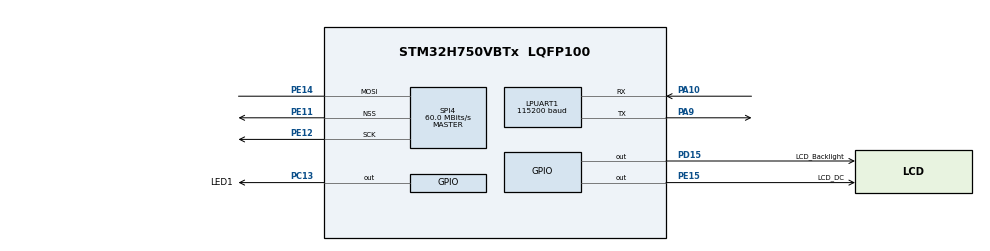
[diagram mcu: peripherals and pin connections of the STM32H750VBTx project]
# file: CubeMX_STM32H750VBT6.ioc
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CORTEX_M7.CPU_DCache=Enabled
CORTEX_M7.CPU_ICache=Enabled
CORTEX_M7.Enable-Cortex_Memory_Protection_Unit_Region0_Settings=MPU_REGION_ENABLE
CORTEX_M7.MPU_Control=__NULL
LPUART1.BaudRate=115200
Mcu.Family=STM32H7
Mcu.Name=STM32H750VBTx
Mcu.Package=LQFP100
NVIC.LPUART1_IRQn=true\:0\:0\:false\:false\:true\:true\:true\:true
NVIC.PriorityGroup=NVIC_PRIORITYGROUP_4
PA10.Mode=Asynchronous
PA10.Signal=LPUART1_RX
PA13\ (JTMS/SWDIO).Mode=Serial_Wire
PA13\ (JTMS/SWDIO).Signal=DEBUG_JTMS-SWDIO
PA14\ (JTCK/SWCLK).Mode=Serial_Wire
PA14\ (JTCK/SWCLK).Signal=DEBUG_JTCK-SWCLK
PA9.Mode=Asynchronous
PA9.Signal=LPUART1_TX
PC13.GPIO_Label=LED1
PC13.PinState=GPIO_PIN_RESET
PC13.Signal=GPIO_Output
PC14-OSC32_IN\ (OSC32_IN).Mode=LSE-External-Oscillator
PC14-OSC32_IN\ (OSC32_IN).Signal=RCC_OSC32_IN
PC15-OSC32_OUT\ (OSC32_OUT).Mode=LSE-External-Oscillator
PC15-OSC32_OUT\ (OSC32_OUT).Signal=RCC_OSC32_OUT
PD15.GPIO_Label=LCD_Backlight
PD15.Signal=GPIO_Output
PE11.GPIO_Speed=GPIO_SPEED_FREQ_VERY_HIGH
PE11.Mode=NSS_Signal_Hard_Output
PE11.Signal=SPI4_NSS
PE12.GPIO_Speed=GPIO_SPEED_FREQ_VERY_HIGH
PE12.Mode=Simplex_Bidirectional_Master
PE12.Signal=SPI4_SCK
PE14.GPIO_Speed=GPIO_SPEED_FREQ_VERY_HIGH
PE14.Mode=Simplex_Bidirectional_Master
PE14.Signal=SPI4_MOSI
PE15.GPIO_Label=LCD_DC
PE15.Signal=GPIO_Output
PH0-OSC_IN\ (PH0).Mode=HSE-External-Oscillator
PH0-OSC_IN\ (PH0).Signal=RCC_OSC_IN
PH1-OSC_OUT\ (PH1).Mode=HSE-External-Oscillator
PH1-OSC_OUT\ (PH1).Signal=RCC_OSC_OUT
ProjectManager.HeapSize=0x200
ProjectManager.StackSize=0x1000
ProjectManager.TargetToolchain=STM32CubeIDE
RCC.ADCFreq_Value=50390625
RCC.APB1Freq_Value=120000000
RCC.APB2Freq_Value=120000000
RCC.APB3Freq_Value=120000000
RCC.APB4Freq_Value=120000000
RCC.CortexFreq_Value=480000000
RCC.D1PPRE=RCC_APB3_DIV2
RCC.D2PPRE1=RCC_APB1_DIV2
RCC.D2PPRE2=RCC_APB2_DIV2
RCC.D3PPRE=RCC_APB4_DIV2
RCC.DIVM1=5
RCC.DIVN1=192
RCC.HCLKFreq_Value=240000000
RCC.HPRE=RCC_HCLK_DIV2
RCC.PLLSourceVirtual=RCC_PLLSOURCE_HSE
RCC.SYSCLKFreq_VALUE=480000000
RCC.SYSCLKSource=RCC_SYSCLKSOURCE_PLLCLK
RCC.USBFreq_Value=480000000
SPI4.CalculateBaudRate=60.0 MBits/s
SPI4.DataSize=SPI_DATASIZE_8BIT
SPI4.Direction=SPI_DIRECTION_1LINE
SPI4.FifoThreshold=SPI_FIFO_THRESHOLD_02DATA
SPI4.Mode=SPI_MODE_MASTER
SPI4.VirtualNSS=VM_NSSHARD
SPI4.VirtualType=VM_MASTER
board=custom

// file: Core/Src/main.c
/* USER CODE BEGIN Header */
/**
 ******************************************************************************
 * @file           : main.c
 * @brief          : Main program body
 ******************************************************************************
 * @attention
 *
 * Copyright (c) 2024 STMicroelectronics.
 * All rights reserved.
 *
 * This software is licensed under terms that can be found in the LICENSE file
 * in the root directory of this software component.
 * If no LICENSE file comes with this software, it is provided AS-IS.
 *
 ******************************************************************************
 */
/* USER CODE END Header */
#include "main.h"
#include "usart.h"
#include "spi.h"
#include "gpio.h"

/* USER CODE BEGIN Includes */
#include "led.h"
#include "lcd_169.h"

/* USER CODE END Includes */

void SystemClock_Config(void);

int main(void)
{
/* Enable the CPU Cache */

  /* Enable I-Cache---------------------------------------------------------*/
  SCB_EnableICache();

  /* Enable D-Cache---------------------------------------------------------*/
  SCB_EnableDCache();

  /* MCU Configuration--------------------------------------------------------*/

  /* Reset of all peripherals, Initializes the Flash interface and the Systick. */
  HAL_Init();

  /* USER CODE BEGIN Init */
  LED_Init();
  /* USER CODE END Init */

  /* Configure the system clock */
  SystemClock_Config();

  /* Initialize all configured peripherals */
  MX_GPIO_Init();
  MX_LPUART1_UART_Init();
  MX_SPI4_Init();

  /* Infinite loop */
  while (1)
  {

  }
}

void SystemClock_Config(void)
{
  RCC_OscInitTypeDef RCC_OscInitStruct = {0};
  RCC_ClkInitTypeDef RCC_ClkInitStruct = {0};

  /** Supply configuration update enable
  */
  HAL_PWREx_ConfigSupply(PWR_LDO_SUPPLY);

  /** Configure the main internal regulator output voltage
  */
  __HAL_PWR_VOLTAGESCALING_CONFIG(PWR_REGULATOR_VOLTAGE_SCALE1);

  while(!__HAL_PWR_GET_FLAG(PWR_FLAG_VOSRDY)) {}

  __HAL_RCC_SYSCFG_CLK_ENABLE();
  __HAL_PWR_VOLTAGESCALING_CONFIG(PWR_REGULATOR_VOLTAGE_SCALE0);

  while(!__HAL_PWR_GET_FLAG(PWR_FLAG_VOSRDY)) {}

  /** Initializes the RCC Oscillators according to the specified parameters
  * in the RCC_OscInitTypeDef structure.
  */
  RCC_OscInitStruct.OscillatorType = RCC_OSCILLATORTYPE_HSE;
  RCC_OscInitStruct.HSEState = RCC_HSE_ON;
  RCC_OscInitStruct.PLL.PLLState = RCC_PLL_ON;
  RCC_OscInitStruct.PLL.PLLSource = RCC_PLLSOURCE_HSE;
  RCC_OscInitStruct.PLL.PLLM = 5;
  RCC_OscInitStruct.PLL.PLLN = 192;
  RCC_OscInitStruct.PLL.PLLP = 2;
  RCC_OscInitStruct.PLL.PLLQ = 2;
  RCC_OscInitStruct.PLL.PLLR = 2;
  RCC_OscInitStruct.PLL.PLLRGE = RCC_PLL1VCIRANGE_2;
  RCC_OscInitStruct.PLL.PLLVCOSEL = RCC_PLL1VCOWIDE;
  RCC_OscInitStruct.PLL.PLLFRACN = 0;
  if (HAL_RCC_OscConfig(&RCC_OscInitStruct) != HAL_OK)
  {
    Error_Handler();
  }

  /** Initializes the CPU, AHB and APB buses clocks
  */
  RCC_ClkInitStruct.ClockType = RCC_CLOCKTYPE_HCLK|RCC_CLOCKTYPE_SYSCLK
                              |RCC_CLOCKTYPE_PCLK1|RCC_CLOCKTYPE_PCLK2
                              |RCC_CLOCKTYPE_D3PCLK1|RCC_CLOCKTYPE_D1PCLK1;
  RCC_ClkInitStruct.SYSCLKSource = RCC_SYSCLKSOURCE_PLLCLK;
  RCC_ClkInitStruct.SYSCLKDivider = RCC_SYSCLK_DIV1;
  RCC_ClkInitStruct.AHBCLKDivider = RCC_HCLK_DIV2;
  RCC_ClkInitStruct.APB3CLKDivider = RCC_APB3_DIV2;
  RCC_ClkInitStruct.APB1CLKDivider = RCC_APB1_DIV2;
  RCC_ClkInitStruct.APB2CLKDivider = RCC_APB2_DIV2;
  RCC_ClkInitStruct.APB4CLKDivider = RCC_APB4_DIV2;

  if (HAL_RCC_ClockConfig(&RCC_ClkInitStruct, FLASH_LATENCY_4) != HAL_OK)
  {
    Error_Handler();
  }
}

void Error_Handler(void)
{
  __disable_irq();
  while (1)
  {
  }
}
